# MCAN register map
Vendor: Texas Instruments
Peripheral module from a debugger description file (folder UCD3138R064RSM).
Registers are 32-bit, access per field, no defined reset value unless marked. A register's access mark holds for its fields unless they carry their own. Offsets are as the file gives them; lines under a group give offsets from that group; [hi:lo] are bit positions; {n}, {i} and the like mark numbered series; 'fields as' and 'values as' point back to an identical list; <NAME> marks a mode.

## MCAN (part 1 of 2)
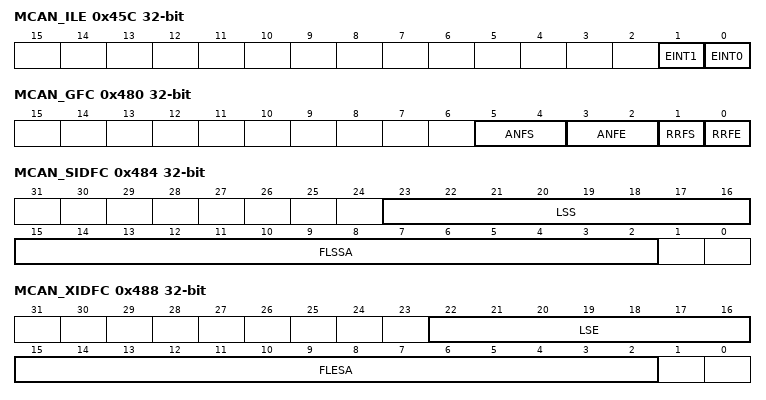
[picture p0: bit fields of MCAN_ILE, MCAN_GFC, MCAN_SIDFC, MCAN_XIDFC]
0x45C MCAN_ILE — MCAN Interrupt Line Enable
  [1] EINT1 rw — Enable Interrupt Line 1 #br# 0 Interrupt Line 1 is disabled #br# 1 Interrupt Line 1 is enabled
  [0] EINT0 rw — Enable Interrupt Line 0 #br# 0 Interrupt Line 0 is disabled #br# 1 Interrupt Line 0 is enabled
0x480 MCAN_GFC — MCAN Global Filter Configuration
  [5:4] ANFS rw — Accept Non-matching Frames Standard. Defines how received messages with 11-bit IDs that do not match any element of the filter list are treated. #br# 00 Accept in Rx FIFO 0 #br# 01 Accept in Rx FIFO 1 #br# 10 Reject #br# 11 Reject #br# #br#Qualified Write is possible only with CCCR.CCE='1' and CCCR.INIT='1'.
  [3:2] ANFE rw — Accept Non-matching Frames Extended. Defines how received messages with 29-bit IDs that do not match any element of the filter list are treated. #br# 00 Accept in Rx FIFO 0 #br# 01 Accept in Rx FIFO 1 #br# 10 Reject #br# 11 Reject #br# #br#Qualified Write is possible only with CCCR.CCE='1' and CCCR.INIT='1'.
  [1] RRFS rw — Reject Remote Frames Standard #br# 0 Filter remote frames with 11-bit standard IDs #br# 1 Reject all remote frames with 11-bit standard IDs #br# #br#Qualified Write is possible only with CCCR.CCE='1' and CCCR.INIT='1'.
  [0] RRFE rw — Reject Remote Frames Extended #br# 0 Filter remote frames with 29-bit extended IDs #br# 1 Reject all remote frames with 29-bit extended IDs #br# #br#Qualified Write is possible only with CCCR.CCE='1' and CCCR.INIT='1'.
0x484 MCAN_SIDFC — MCAN Standard ID Filter Configuration
  [23:16] LSS rw — List Size Standard #br# 0 No standard Message ID filter #br# 1-128 Number of standard Message ID filter elements #br# >128 Values greater than 128 are interpreted as 128
  [15:2] FLSSA rw — Filter List Standard Start Address. Start address of standard Message ID filter list (32-bit word address).
0x488 MCAN_XIDFC — MCAN Extended ID Filter Configuration
  [22:16] LSE rw — List Size Extended #br# 0 No extended Message ID filter #br# 1-64 Number of extended Message ID filter elements #br# >64 Values greater than 64 are interpreted as 64 #br# #br#Qualified Write is possible only with CCCR.CCE='1' and CCCR.INIT='1'.
  [15:2] FLESA rw — Filter List Extended Start Address. Start address of extended Message ID filter list (32-bit word address). #br# #br#Qualified Write is possible only with CCCR.CCE='1' and CCCR.INIT='1'.
0x490 MCAN_XIDAM — MCAN Extended ID and Mask
  [28:0] EIDM rw — Extended ID Mask. For acceptance filtering of extended frames the Extended ID AND Mask is ANDed with the Message ID of a received frame. Intended for masking of 29-bit IDs in SAE J1939. With the reset value of all bits set to one the mask is not active. #br# #br#Qualified Write is possible only with CCCR.CCE='1' and CCCR.INIT='1'.
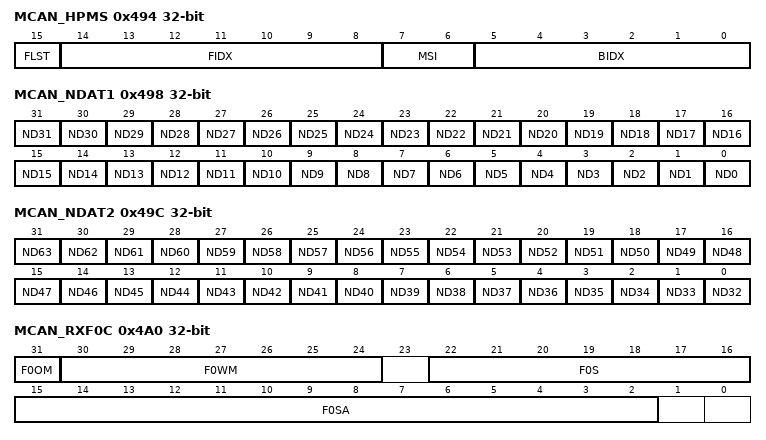
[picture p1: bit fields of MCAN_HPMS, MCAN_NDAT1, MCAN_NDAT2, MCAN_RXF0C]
0x494 MCAN_HPMS ro — This register is updated every time a Message ID filter element configured to generate a priority event matches. This can be used to monitor the status of incoming high priority messages and to enable fast access to these messages.
  [15] FLST — Filter List. Indicates the filter list of the matching filter element. #br# 0 Standard Filter List #br# 1 Extended Filter List
  [14:8] FIDX — Filter Index. Index of matching filter element. Range is 0 to SIDFC.LSS - 1 resp. XIDFC.LSE - 1.
  [7:6] MSI — Message Storage Indicator #br# 00 No FIFO selected #br# 01 FIFO message lost #br# 10 Message stored in FIFO 0 #br# 11 Message stored in FIFO 1
  [5:0] BIDX — Buffer Index. Index of Rx FIFO element to which the message was stored. Only valid when MSI[1] = '1'.
0x498 MCAN_NDAT1 rw — MCAN New Data 1
  [n] ND{n} (n=0..31) — New Data RX Buffer {n} #br# 0 Rx Buffer not updated #br# 1 Rx Buffer updated from new message
0x49C MCAN_NDAT2 rw — MCAN New Data 2
  [n-32] ND{n} (n=32..63) — New Data RX Buffer {n} #br# 0 Rx Buffer not updated #br# 1 Rx Buffer updated from new message
0x4A0 MCAN_RXF0C — MCAN Rx FIFO 0 Configuration
  [31] F0OM rw — FIFO 0 Operation Mode. FIFO 0 can be operated in blocking or in overwrite mode. #br# 0 FIFO 0 blocking mode #br# 1 FIFO 0 overwrite mode #br# #br#Qualified Write is possible only with CCCR.CCE='1' and CCCR.INIT='1'.
  [30:24] F0WM rw — Rx FIFO 0 Watermark #br# 0 Watermark interrupt disabled #br# 1-64 Level for Rx FIFO 0 watermark interrupt (IR.RF0W) #br# >64 Watermark interrupt disabled #br# #br#Qualified Write is possible only with CCCR.CCE='1' and CCCR.INIT='1'.
  [22:16] F0S rw — Rx FIFO 0 Size. The Rx FIFO 0 elements are indexed from 0 to F0S-1. #br# 0 No Rx FIFO 0 #br# 1-64 Number of Rx FIFO 0 elements #br# >64 Values greater than 64 are interpreted as 64 #br# #br#Qualified Write is possible only with CCCR.CCE='1' and CCCR.INIT='1'.
  [15:2] F0SA rw — Rx FIFO 0 Start Address. Start address of Rx FIFO 0 in Message RAM (32-bit word address). #br# #br#Qualified Write is possible only with CCCR.CCE='1' and CCCR.INIT='1'.
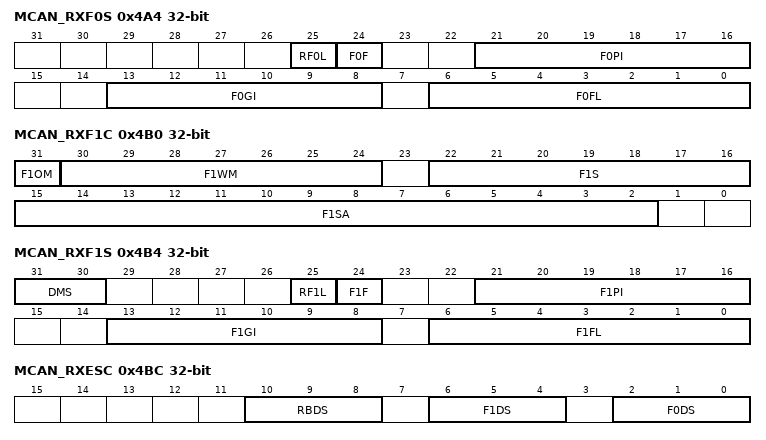
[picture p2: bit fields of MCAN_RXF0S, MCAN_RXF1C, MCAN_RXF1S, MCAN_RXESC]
0x4A4 MCAN_RXF0S ro — MCAN Rx FIFO 0 Status
  [25] RF0L — Rx FIFO 0 Message Lost. This bit is a copy of interrupt flag IR.RF0L. When IR.RF0L is reset, this bit is also reset. #br# 0 No Rx FIFO 0 message lost #br# 1 Rx FIFO 0 message lost, also set after write attempt to Rx FIFO 0 of size zero #br# #br#Note: Overwriting the oldest message when RXF0C.F0OM = '1' will not set this flag.
  [24] F0F — Rx FIFO 0 Full #br# 0 Rx FIFO 0 not full #br# 1 Rx FIFO 0 full
  [21:16] F0PI — Rx FIFO 0 Put Index. Rx FIFO 0 write index pointer, range 0 to 63.
  [13:8] F0GI — Rx FIFO 0 Get Index. Rx FIFO 0 read index pointer, range 0 to 63.
  [6:0] F0FL — Rx FIFO 0 Fill Level. Number of elements stored in Rx FIFO 0, range 0 to 64.
0x4A8 MCAN_RXF0A — MCAN Rx FIFO 0 Acknowledge
  [5:0] F0AI rw — Rx FIFO 0 Acknowledge Index. After the Host has read a message or a sequence of messages from Rx FIFO 0 it has to write the buffer index of the last element read from Rx FIFO 0 to F0AI. This will set the Rx FIFO 0 Get Index RXF0S.F0GI to F0AI + 1 and update the FIFO 0 Fill Level RXF0S.F0FL.
0x4AC MCAN_RXBC — MCAN Rx Buffer Configuration
  [15:2] RBSA rw — Rx Buffer Start Address. Configures the start address of the Rx Buffers section in the Message RAM (32-bit word address). #br# #br#+I466
0x4B0 MCAN_RXF1C — MCAN Rx FIFO 1 Configuration
  [31] F1OM rw — FIFO 1 Operation Mode. FIFO 1 can be operated in blocking or in overwrite mode. #br# 0 FIFO 1 blocking mode #br# 1 FIFO 1 overwrite mode #br# #br#Qualified Write is possible only with CCCR.CCE='1' and CCCR.INIT='1'.
  [30:24] F1WM rw — Rx FIFO 1 Watermark #br# 0 Watermark interrupt disabled #br# 1-64 Level for Rx FIFO 1 watermark interrupt (IR.RF1W) #br# >64 Watermark interrupt disabled #br# #br#Qualified Write is possible only with CCCR.CCE='1' and CCCR.INIT='1'.
  [22:16] F1S rw — Rx FIFO 1 Size. The Rx FIFO 1 elements are indexed from 0 to F1S - 1. #br# 0 No Rx FIFO 1 #br# 1-64 Number of Rx FIFO 1 elements #br# >64 Values greater than 64 are interpreted as 64 #br# #br#Qualified Write is possible only with CCCR.CCE='1' and CCCR.INIT='1'.
  [15:2] F1SA rw — Rx FIFO 1 Start Address Start address of Rx FIFO 1 in Message RAM (32-bit word address).
0x4B4 MCAN_RXF1S ro — MCAN Rx FIFO 1 Status
  [31:30] DMS — Debug Message Status #br# 00 Idle state, wait for reception of debug messages, DMA request is cleared #br# 01 Debug message A received #br# 10 Debug messages A, B received #br# 11 Debug messages A, B, C received, DMA request is set
  [25] RF1L — Rx FIFO 1 Message Lost. This bit is a copy of interrupt flag IR.RF1L. When IR.RF1L is reset, this bit is also reset. #br# 0 No Rx FIFO 1 message lost #br# 1 Rx FIFO 1 message lost, also set after write attempt to Rx FIFO 1 of size zero #br# #br#Note: Overwriting the oldest message when RXF1C.F1OM = '1' will not set this flag.
  [24] F1F — Rx FIFO 1 Full #br# 0 Rx FIFO 1 not full #br# 1 Rx FIFO 1 full
  [21:16] F1PI — Rx FIFO 1 Put Index. Rx FIFO 1 write index pointer, range 0 to 63.
  [13:8] F1GI — Rx FIFO 1 Get Index. Rx FIFO 1 read index pointer, range 0 to 63.
  [6:0] F1FL — Rx FIFO 1 Fill Level. Number of elements stored in Rx FIFO 1, range 0 to 64.
0x4B8 MCAN_RXF1A — MCAN Rx FIFO 1 Acknowledge
  [5:0] F1AI rw — Rx FIFO 1 Acknowledge Index. After the Host has read a message or a sequence of messages from Rx FIFO 1 it has to write the buffer index of the last element read from Rx FIFO 1 to F1AI. This will set the Rx FIFO 1 Get Index RXF1S.F1GI to F1AI + 1 and update the FIFO 1 Fill Level RXF1S.F1FL.
0x4BC MCAN_RXESC — Configures the number of data bytes belonging to an Rx Buffer / Rx FIFO element. Data field sizes >8 bytes are intended for CAN FD operation only.
  [10:8] RBDS rw — Rx Buffer Data Field Size #br# 000 8 byte data field #br# 001 12 byte data field #br# 010 16 byte data field #br# 011 20 byte data field #br# 100 24 byte data field #br# 101 32 byte data field #br# 110 48 byte data field #br# 111 64 byte data field #br# #br#Note: In case the data field size of an accepted CAN frame exceeds the data field size configured for the matching Rx Buffer or Rx FIFO, only the number of bytes as configured by RXESC are stored to the Rx Buffer resp. Rx FIFO element. The rest of the frame's data field is ignored. #br# #br#Qualified Write is possible only with CCCR.CCE='1' and CCCR.INIT='1'.
  [6:4] F1DS rw — Rx FIFO 1 Data Field Size #br# 000 8 byte data field #br# 001 12 byte data field #br# 010 16 byte data field #br# 011 20 byte data field #br# 100 24 byte data field #br# 101 32 byte data field #br# 110 48 byte data field #br# 111 64 byte data field #br# #br#Note: In case the data field size of an accepted CAN frame exceeds the data field size configured for the matching Rx Buffer or Rx FIFO, only the number of bytes as configured by RXESC are stored to the Rx Buffer resp. Rx FIFO element. The rest of the frame's data field is ignored. #br# #br#Qualified Write is possible only with CCCR.CCE='1' and CCCR.INIT='1'.
  [2:0] F0DS rw — Rx FIFO 0 Data Field Size #br# 000 8 byte data field #br# 001 12 byte data field #br# 010 16 byte data field #br# 011 20 byte data field #br# 100 24 byte data field #br# 101 32 byte data field #br# 110 48 byte data field #br# 111 64 byte data field #br# #br#Note: In case the data field size of an accepted CAN frame exceeds the data field size configured for the matching Rx Buffer or Rx FIFO, only the number of bytes as configured by RXESC are stored to the Rx Buffer resp. Rx FIFO element. The rest of the frame's data field is ignored. #br# #br#Qualified Write is possible only with CCCR.CCE='1' and CCCR.INIT='1'.
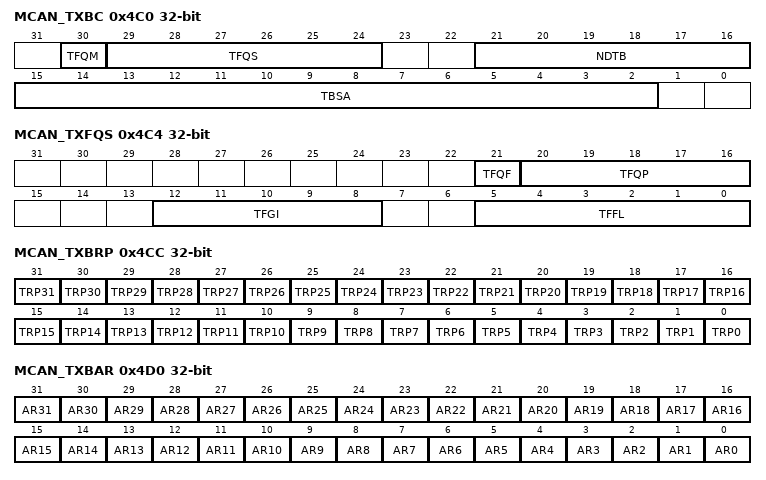
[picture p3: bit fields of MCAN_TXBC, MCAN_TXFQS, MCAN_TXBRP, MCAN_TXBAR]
0x4C0 MCAN_TXBC — MCAN Tx Buffer Configuration
  [30] TFQM rw — Tx FIFO/Queue Mode #br# 0 Tx FIFO operation #br# 1 Tx Queue operation #br# #br#Qualified Write is possible only with CCCR.CCE='1' and CCCR.INIT='1'.
  [29:24] TFQS rw — Transmit FIFO/Queue Size #br# 0 No Tx FIFO/Queue #br# 1-32 Number of Tx Buffers used for Tx FIFO/Queue #br# >32 Values greater than 32 are interpreted as 32 #br# #br#Note: Be aware that the sum of TFQS and NDTB may be not greater than 32. There is no check #br#for erroneous configurations. The Tx Buffers section in the Message RAM starts with the #br#dedicated Tx Buffers. #br# #br#Qualified Write is possible only with CCCR.CCE='1' and CCCR.INIT='1'.
  [21:16] NDTB rw — Number of Dedicated Transmit Buffers #br# 0 No Dedicated Tx Buffers #br# 1-32 Number of Dedicated Tx Buffers #br# >32 Values greater than 32 are interpreted as 32 #br# #br#Note: Be aware that the sum of TFQS and NDTB may be not greater than 32. There is no check #br#for erroneous configurations. The Tx Buffers section in the Message RAM starts with the #br#dedicated Tx Buffers. #br# #br#Qualified Write is possible only with CCCR.CCE='1' and CCCR.INIT='1'.
  [15:2] TBSA rw — Tx Buffers Start Address. Start address of Tx Buffers section in Message RAM (32-bit word address). #br# #br#Qualified Write is possible only with CCCR.CCE='1' and CCCR.INIT='1'.
0x4C4 MCAN_TXFQS ro — The Tx FIFO/Queue status is related to the pending Tx requests listed in register TXBRP. Therefore the effect of Add/Cancellation requests may be delayed due to a running Tx scan (TXBRP not yet updated).
  [21] TFQF — Tx FIFO/Queue Full #br# 0 Tx FIFO/Queue not full #br# 1 Tx FIFO/Queue full
  [20:16] TFQP — Tx FIFO/Queue Put Index. Tx FIFO/Queue write index pointer, range 0 to 31. #br# #br#Note: In case of mixed configurations where dedicated Tx Buffers are combined with a Tx FIFO or a Tx Queue, the Put and Get Indices indicate the number of the Tx Buffer starting with the first dedicated Tx Buffers. Example: For a configuration of 12 dedicated Tx Buffers and a Tx FIFO of 20 Buffers a Put Index of 15 points to the fourth buffer of the Tx FIFO.
  [12:8] TFGI — Tx FIFO Get Index. Tx FIFO read index pointer, range 0 to 31. Read as zero when Tx Queue operation is configured (TXBC.TFQM = '1'). #br# #br#Note: In case of mixed configurations where dedicated Tx Buffers are combined with a Tx FIFO or a Tx Queue, the Put and Get Indices indicate the number of the Tx Buffer starting with the first dedicated Tx Buffers. Example: For a configuration of 12 dedicated Tx Buffers and a Tx FIFO of 20 Buffers a Put Index of 15 points to the fourth buffer of the Tx FIFO.
  [5:0] TFFL — Tx FIFO Free Level. Number of consecutive free Tx FIFO elements starting from TFGI, range 0 to 32. Read as zero when Tx Queue operation is configured (TXBC.TFQM = '1').
0x4C8 MCAN_TXESC — Configures the number of data bytes belonging to a Tx Buffer element. Data field sizes > 8 bytes are intended for CAN FD operation only.
  [2:0] TBDS rw — Tx Buffer Data Field Size #br# 000 8 byte data field #br# 001 12 byte data field #br# 010 16 byte data field #br# 011 20 byte data field #br# 100 24 byte data field #br# 101 32 byte data field #br# 110 48 byte data field #br# 111 64 byte data field #br# #br#Note: In case the data length code DLC of a Tx Buffer element is configured to a value higher than the Tx Buffer data field size TXESC.TBDS, the bytes not defined by the Tx Buffer are transmitted as "0xCC" (padding bytes). #br# #br#Qualified Write is possible only with CCCR.CCE='1' and CCCR.INIT='1'.
0x4CC MCAN_TXBRP ro — MCAN Tx Buffer Request Pending
  [n] TRP{n} (n=1..31) — Transmission Request Pending {n}. See description for bit 0.
  [0] TRP0 — Transmission Request Pending 0. #br# #br#Each Tx Buffer has its own Transmission Request Pending bit. The bits are set via register TXBAR. The bits are reset after a requested transmission has completed or has been cancelled via register TXBCR. #br# #br#TXBRP bits are set only for those Tx Buffers configured via TXBC. After a TXBRP bit has been set, a Tx scan is started to check for the pending Tx request with the highest priority (Tx Buffer with lowest Message ID). #br# #br#A cancellation request resets the corresponding transmission request pending bit of register TXBRP. In case a transmission has already been started when a cancellation is requested, this is done at the end of the transmission, regardless whether the transmission was successful or not. The cancellation request bits are reset directly after the corresponding TXBRP bit has been reset. #br# #br#After a cancellation has been requested, a finished cancellation is signalled via TXBCF #br#- after successful transmission together with the corresponding TXBTO bit #br#- when the transmission has not yet been started at the point of cancellation #br#- when the transmission has been aborted due to lost arbitration #br#- when an error occurred during frame transmission #br# #br#In DAR mode all transmissions are automatically cancelled if they are not successful. The corresponding TXBCF bit is set for all unsuccessful transmissions. #br# 0 No transmission request pending #br# 1 Transmission request pending #br# #br#Note: TXBRP bits which are set while a Tx scan is in progress are not considered during this particular Tx scan. In case a cancellation is requested for such a Tx Buffer, this Add Request is cancelled immediately, the corresponding TXBRP bit is reset.
0x4D0 MCAN_TXBAR rw — MCAN Tx Buffer Add Request
  [n] AR{n} (n=1..31) — Add Request {n}. See description for bit 0.
  [0] AR0 — Add Request 0. #br# #br#Each Tx Buffer has its own Add Request bit. Writing a '1' will set the corresponding Add Request bit; writing a '0' has no impact. This enables the Host to set transmission requests for multiple Tx Buffers with one write to TXBAR. TXBAR bits are set only for those Tx Buffers configured via TXBC. When no Tx scan is running, the bits are reset immediately, else the bits remain set until the Tx scan process has completed. #br# 0 No transmission request added #br# 1 Transmission requested added #br# #br#Note: If an add request is applied for a Tx Buffer with pending transmission request (corresponding TXBRP bit already set), this add request is ignored. #br# #br#Qualified Write is possible only with CCCR.CCE='0'
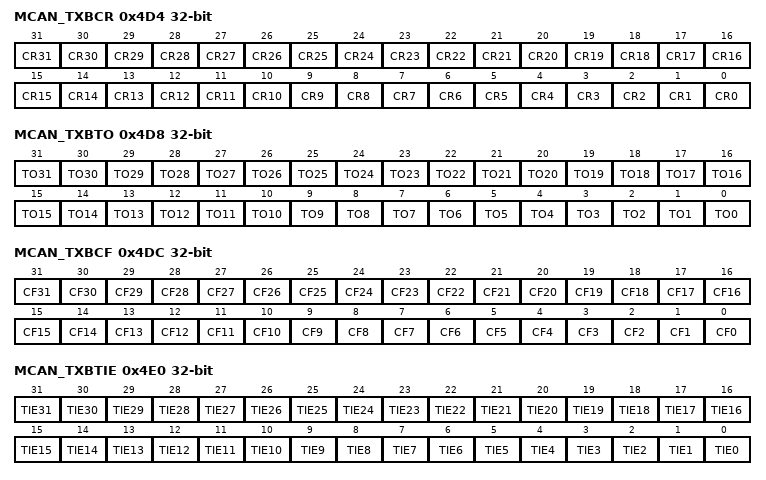
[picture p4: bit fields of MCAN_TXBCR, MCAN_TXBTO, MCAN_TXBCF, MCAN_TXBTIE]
0x4D4 MCAN_TXBCR rw — MCAN Tx Buffer Cancellation Request
  [n] CR{n} (n=1..31) — Cancellation Request {n}. See description for bit 0.
  [0] CR0 — Cancellation Request 0. #br# #br#Each Tx Buffer has its own Cancellation Request bit. Writing a '1' will set the corresponding Cancellation Request bit; writing a '0' has no impact. This enables the Host to set cancellation requests for multiple Tx Buffers with one write to TXBCR. TXBCR bits are set only for those Tx Buffers configured via TXBC. The bits remain set until the corresponding bit of TXBRP is reset. #br# 0 No cancellation pending #br# 1 Cancellation pending #br# #br#Qualified Write is possible only with CCCR.CCE='0'
0x4D8 MCAN_TXBTO ro — MCAN Tx Buffer Transmission Occurred
  [n] TO{n} (n=1..31) — Transmission Occurred {n}. See description for bit 0.
  [0] TO0 — Transmission Occurred 0. #br# #br#Each Tx Buffer has its own Transmission Occurred bit. The bits are set when the corresponding TXBRP bit is cleared after a successful transmission. The bits are reset when a new transmission is requested by writing a '1' to the corresponding bit of register TXBAR. #br# 0 No transmission occurred #br# 1 Transmission occurred
0x4DC MCAN_TXBCF ro — MCAN Tx Buffer Cancellation Finished
  [n] CF{n} (n=1..31) — Cancellation Finished {n}. See description for bit 0.
  [0] CF0 — Cancellation Finished 0. #br# #br#Each Tx Buffer has its own Cancellation Finished bit. The bits are set when the corresponding TXBRP bit is cleared after a cancellation was requested via TXBCR. In case the corresponding TXBRP bit was not set at the point of cancellation, CF is set immediately. The bits are reset when a new transmission is requested by writing a '1' to the corresponding bit of register TXBAR. #br# 0 No transmit buffer cancellation #br# 1 Transmit buffer cancellation finished
0x4E0 MCAN_TXBTIE rw — Each Tx Buffer has its own Transmission Interrupt Enable bit.
  [n] TIE{n} (n=1..31) — Transmission Interrupt Enable {n}. Each Tx Buffer has its own Transmission Interrupt Enable bit. #br# 0 Transmission interrupt disabled #br# 1 Transmission interrupt enable
  [0] TIE0 — Transmission Interrupt Enable 0. #br# 0 Transmission interrupt disabled #br# 1 Transmission interrupt enable
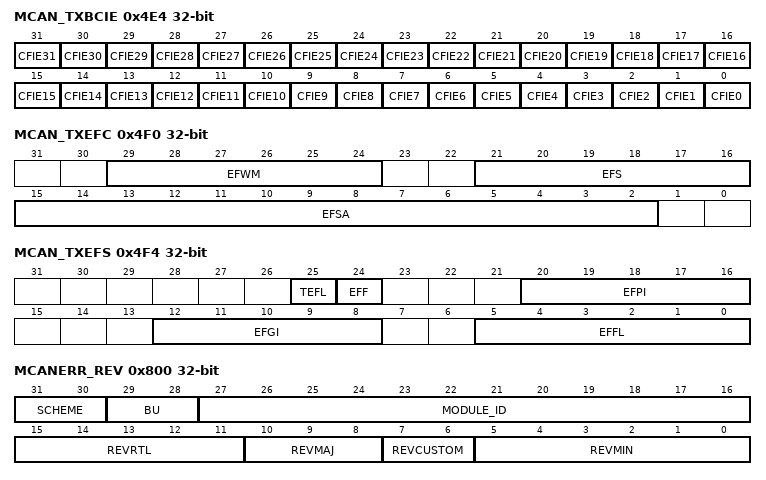
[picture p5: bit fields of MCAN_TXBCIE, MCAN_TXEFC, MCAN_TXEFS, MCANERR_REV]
0x4E4 MCAN_TXBCIE rw — MCAN Tx Buffer Cancellation Finished Interrupt Enable
  [n] CFIE{n} (n=0..31) — Cancellation Finished Interrupt Enable {n}. Each Tx Buffer has its own Cancellation Finished Interrupt Enable bit. #br# 0 Cancellation finished interrupt disabled #br# 1 Cancellation finished interrupt enabled
0x4F0 MCAN_TXEFC — MCAN Tx Event FIFO Configuration
  [29:24] EFWM rw — Event FIFO Watermark #br# 0 Watermark interrupt disabled #br# 1-32 Level for Tx Event FIFO watermark interrupt (IR.TEFW) #br# >32 Watermark interrupt disabled
  [21:16] EFS rw — Event FIFO Size. The Tx Event FIFO elements are indexed from 0 to EFS - 1. #br# 0 Tx Event FIFO disabled #br# 1-32 Number of Tx Event FIFO elements #br# >32 Values greater than 32 are interpreted as 32
  [15:2] EFSA rw — Event FIFO Start Address. Start address of Tx Event FIFO in Message RAM (32-bit word address).
0x4F4 MCAN_TXEFS ro — MCAN Tx Event FIFO Status
  [25] TEFL — Tx Event FIFO Element Lost. This bit is a copy of interrupt flag IR.TEFL. When IR.TEFL is reset, this bit is also reset. #br# 0 No Tx Event FIFO element lost #br# 1 Tx Event FIFO element lost, also set after write attempt to Tx Event FIFO of size zero.
  [24] EFF — Event FIFO Full #br# 0 Tx Event FIFO not full #br# 1 Tx Event FIFO full
  [20:16] EFPI — Event FIFO Put Index.Tx Event FIFO write index pointer, range 0 to 31.
  [12:8] EFGI — Event FIFO Get Index. Tx Event FIFO read index pointer, range 0 to 31.
  [5:0] EFFL — Event FIFO Fill Level. Number of elements stored in Tx Event FIFO, range 0 to 32.
0x4F8 MCAN_TXEFA — MCAN Tx Event FIFO Acknowledge
  [4:0] EFAI rw — Event FIFO Acknowledge Index. After the Host has read an element or a sequence of elements from the Tx Event FIFO it has to write the index of the last element read from Tx Event FIFO to EFAI. This will set the Tx Event FIFO Get Index TXEFS.EFGI to EFAI + 1 and update the Event FIFO Fill Level TXEFS.EFFL.
0x800 MCANERR_REV ro — MCAN Error Aggregator Revision Register
  [31:30] SCHEME — PID Register Scheme
  [29:28] BU — Business Unit: 0x2 = Processors
  [27:16] MODULE_ID — Module Identification Number
  [15:11] REVRTL — RTL revision. Will vary depending on release
  [10:8] REVMAJ — Major Revision of the Error Aggregator
  [7:6] REVCUSTOM — Custom Revision of the Error Aggregator
  [5:0] REVMIN — Minor Revision of the Error Aggregator
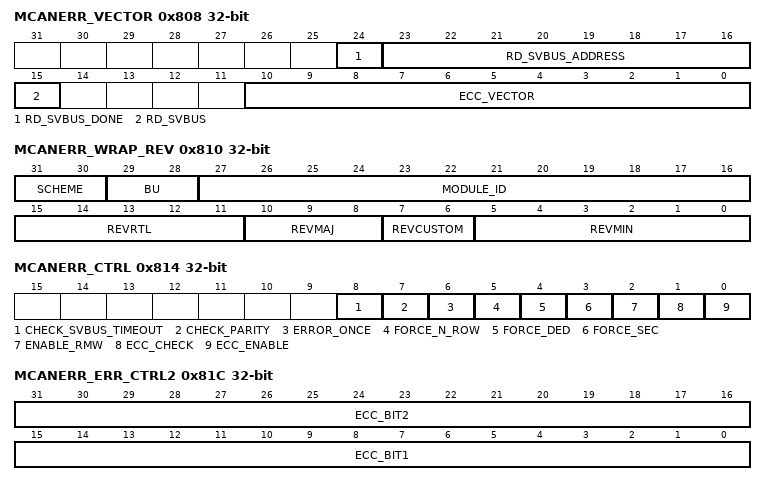
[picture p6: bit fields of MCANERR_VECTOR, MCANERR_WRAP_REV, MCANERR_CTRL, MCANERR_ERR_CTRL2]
0x808 MCANERR_VECTOR — Each error detection and correction (EDC) controller has a bank of error registers (offsets 0x10 - 0x3B) associated with it. These registers are accessed via an internal serial bus (SVBUS). To access them through the ECC aggregator the controller ID desired must be written to the ECC_VECTOR field, together with the RD_SVBUS trigger and RD_SVBUS_ADDRESS bit field. This initiates the serial read which consummates by setting the RD_SVBUS_DONE bit. At this point the addressed register may be read by a normal CPU read of the appropriate offset address.
  [24] RD_SVBUS_DONE ro — Read Completion Flag
  [23:16] RD_SVBUS_ADDRESS rw — Read Address Offset
  [15] RD_SVBUS rw — Read Trigger
  [10:0] ECC_VECTOR rw — ECC RAM ID. Each error detection and correction (EDC) controller has a bank of error registers (offsets 0x10 - 0x3B) associated with it. These registers are accessed via an internal serial bus (SVBUS). To access them through the ECC aggregator the controller ID desired must be written to the ECC_VECTOR field, together with the RD_SVBUS trigger and RD_SVBUS_ADDRESS bit field. This initiates the serial read which consummates by setting the RD_SVBUS_DONE bit. At this point the addressed register may be read by a normal CPU read of the appropriate offset address. #br# 0x000 Message RAM ECC controller is selected #br# Others Reserved (do not use) #br# #br#Subsequent writes through the SVBUS (offsets 0x10 - 0x3B) have a delayed completion. To avoid conflicts, perform a read back of a register within this range after writing.
0x80C MCANERR_STAT ro — MCAN Error Misc Status
  [10:0] NUM_RAMS — Number of RAMs. Number of ECC RAMs serviced by the aggregator.
0x810 MCANERR_WRAP_REV ro — This register is accessed through the ECC aggregator via an internal serial bus. To access, the appropriate procedure must be first followed in the MCAN ECC Vector Register.
  fields as MCANERR_REV
0x814 MCANERR_CTRL — This register is accessed through the ECC aggregator via an internal serial bus. To access, the appropriate procedure must be first followed in the MCAN ECC Vector Register.
  [8] CHECK_SVBUS_TIMEOUT rw — Enables Serial VBUS timeout mechanism
  [7] CHECK_PARITY rw — Enables parity checking on internal data
  [6] ERROR_ONCE rw — If this bit is set, the FORCE_SEC/FORCE_DED will inject an error to the specified row only once. The FORCE_SEC bit will be cleared once a writeback happens. If writeback is not enabled, this error will be cleared the cycle following the read when the data is corrected. For double-bit errors, the FORCE_DED bit will be cleared the cycle following the double-bit error. Any subsequent reads will not force an error.
  [5] FORCE_N_ROW rw — Enable single/double-bit error on the next RAM read, regardless of the MCANERR_ERR_CTRL1.ECC_ROW setting. For write through mode, this applies to writes as well as reads.
  [4] FORCE_DED rw — Force double-bit error. Cleared the cycle following the error if ERROR_ONCE is asserted. For write through mode, this applies to writes as well as reads. MCANERR_ERR_CTRL1 and MCANERR_ERR_CTRL2 should be configured prior to setting this bit.
  [3] FORCE_SEC rw — Force single-bit error. Cleared on a writeback or the cycle following the error if ERROR_ONCE is asserted. For write through mode, this applies to writes as well as reads. MCANERR_ERR_CTRL1 and MCANERR_ERR_CTRL2 should be configured prior to setting this bit.
  [2] ENABLE_RMW rw — Enable read-modify-write on partial word writes
  [1] ECC_CHECK rw — Enable ECC Check. ECC is completely bypassed if both ECC_ENABLE and ECC_CHECK are '0'.
  [0] ECC_ENABLE rw — Enable ECC Generation
0x818 MCANERR_ERR_CTRL1 rw — This register is accessed through the ECC aggregator via an internal serial bus. To access, the appropriate procedure must be first followed in the MCAN ECC Vector Register.
  [31:0] ECC_ROW — Row address where FORCE_SEC or FORCE_DED needs to be applied. This is ignored if FORCE_N_ROW is set.
0x81C MCANERR_ERR_CTRL2 rw — This register is accessed through the ECC aggregator via an internal serial bus. To access, the appropriate procedure must be first followed in the MCAN ECC Vector Register.
  [31:16] ECC_BIT2 — Second column/data bit that needs to be flipped when FORCE_DED is set
  [15:0] ECC_BIT1 — Column/Data bit that needs to be flipped when FORCE_SEC or FORCE_DED is set
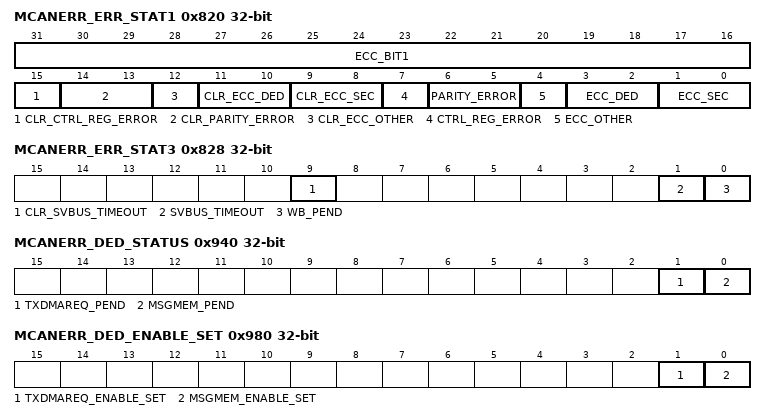
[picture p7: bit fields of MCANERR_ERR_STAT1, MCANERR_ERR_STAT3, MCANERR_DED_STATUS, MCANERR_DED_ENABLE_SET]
0x820 MCANERR_ERR_STAT1 — This register is accessed through the ECC aggregator via an internal serial bus. To access, the appropriate procedure must be first followed in the MCAN ECC Vector Register.
  [31:16] ECC_BIT1 ro — ECC Error Bit Position. Indicates the bit position in the RAM data that is in error on an SEC error. Only valid on an SEC error. #br# 0 Bit 0 is in error #br# 1 Bit 1 is in error #br# 2 Bit 2 is in error #br# 3 Bit 3 is in error #br# ... #br# 31 Bit 31 is in error #br# >32 Invalid
  [15] CLR_CTRL_REG_ERROR rw — Writing a '1' clears the CTRL_REG_ERROR bit
  [14:13] CLR_PARITY_ERROR rw — Clear Parity Error. A write of a non-zero value to this bit field decrements the PARITY_ERROR bit field by the value provided.
  [12] CLR_ECC_OTHER rw — Writing a '1' clears the ECC_OTHER bit.
  [11:10] CLR_ECC_DED rw — Clear ECC_DED. A write of a non-zero value to this bit field decrements the ECC_DED bit field by the value provided.
  [9:8] CLR_ECC_SEC rw — Clear ECC_SEC. A write of a non-zero value to this bit field decrements the ECC_SEC bit field by the value provided.
  [7] CTRL_REG_ERROR rw — Control Register Error. A bit field in the control register is in an ambiguous state. This means that the redundancy registers have detected a state where not all values are the same and has defaulted to the reset state. S/W needs to re-write these registers to a known state. A write of 1 will set this interrupt flag.
  [6:5] PARITY_ERROR rw — Parity Error Status. A 2-bit saturating counter of the number of parity errors that have occurred since last cleared. #br# #br# 0 No parity error detected #br# 1 One parity error was detected #br# 2 Two parity errors were detected #br# 3 Three parity errors were detected #br# #br#A write of a non-zero value to this bit field increments it by the value provided.
  [4] ECC_OTHER rw — SEC While Writeback Error Status #br# 0 No SEC error while writeback pending #br# 1 Indicates that successive single-bit errors have occurred while a writeback is still pending
  [3:2] ECC_DED rw — Double Bit Error Detected Status. A 2-bit saturating counter of the number of DED errors that have occurred since last cleared. #br# #br# 0 No double-bit error detected #br# 1 One double-bit error was detected #br# 2 Two double-bit errors were detected #br# 3 Three double-bit errors were detected #br# #br#A write of a non-zero value to this bit field increments it by the value provided.
  [1:0] ECC_SEC rw — Single Bit Error Corrected Status. A 2-bit saturating counter of the number of SEC errors that have occurred since last cleared. #br# #br# 0 No single-bit error detected #br# 1 One single-bit error was detected and corrected #br# 2 Two single-bit errors were detected and corrected #br# 3 Three single-bit errors were detected and corrected #br# #br#A write of a non-zero value to this bit field increments it by the value provided.
0x824 MCANERR_ERR_STAT2 ro — This register is accessed through the ECC aggregator via an internal serial bus. To access, the appropriate procedure must be first followed in the MCAN ECC Vector Register.
  [31:0] ECC_ROW — Indicates the row address where the single or double-bit error occurred. This value is address offset/4.
0x828 MCANERR_ERR_STAT3 — This register is accessed through the ECC aggregator via an internal serial bus. To access, the appropriate procedure must be first followed in the MCAN ECC Vector Register.
  [9] CLR_SVBUS_TIMEOUT rw — Write 1 to clear the Serial VBUS Timeout Flag
  [1] SVBUS_TIMEOUT rw — Serial VBUS Timeout Flag. Write 1 to set.
  [0] WB_PEND ro — Delayed Write Back Pending Status #br# 0 No write back pending #br# 1 An ECC data correction write back is pending
0x83C MCANERR_SEC_EOI — MCAN Single Error Corrected End of Interrupt Register
  [0] EOI_WR rw — Write to this register indicates that software has acknowledged the pending interrupt and the next interrupt can be sent to the host. #br# #br#Note that a write to the MCANERR_ERR_STAT1.CLR_ECC_SEC goes through the SVBUS and has a delayed completion. To avoid an additional interrupt, read the MCANERR_ERR_STAT1 register back prior to writing to this bit field.
0x840 MCANERR_SEC_STATUS — MCAN Single Error Corrected Interrupt Status Register
  [0] MSGMEM_PEND rw — Message RAM SEC Interrupt Pending #br# 0 No SEC interrupt is pending #br# 1 SEC interrupt is pending
0x880 MCANERR_SEC_ENABLE_SET — MCAN Single Error Corrected Interrupt Enable Set Register
  [0] MSGMEM_ENABLE_SET rw — Message RAM SEC Interrupt Pending Enable Set. Writing a 1 to this bit enables the Message RAM SEC error interrupts. Writing a 0 has no effect. Reads return the corresponding enable bit's current value.
0x8C0 MCANERR_SEC_ENABLE_CLR — MCAN Single Error Corrected Interrupt Enable Clear Register
  [0] MSGMEM_ENABLE_CLR rw — Message RAM SEC Interrupt Pending Enable Clear. Writing a 1 to this bit disables the Message RAM SEC error interrupts. Writing a 0 has no effect. Reads return the corresponding enable bit's current value.
0x93C MCANERR_DED_EOI — MCAN Double Error Detected End of Interrupt Register
  [0] EOI_WR rw — Write to this register indicates that software has acknowledged the pending interrupt and the next interrupt can be sent to the host. #br# #br#Note that a write to the MCANERR_ERR_STAT1.CLR_ECC_DED goes through the SVBUS and has a delayed completion. To avoid an additional interrupt, read the MCANERR_ERR_STAT1 register back prior to writing to this bit field.
0x940 MCANERR_DED_STATUS — MCAN Double Error Detected Interrupt Status Register
  [1] TXDMAREQ_PEND rw — TX Empty DMA Request Parity Interrupt Pending #br# 0 No parity error interrupt is pending #br# 1 A parity error interrupt is pending
  [0] MSGMEM_PEND rw — Message RAM DED Interrupt Pending #br# 0 No DED interrupt is pending #br# 1 DED interrupt is pending
0x980 MCANERR_DED_ENABLE_SET — MCAN Double Error Detected Interrupt Enable Set Register
  [1] TXDMAREQ_ENABLE_SET rw — TX Empty DMA Request Parity Interrupt Pending Enable Set. Writing a 1 to this bit enables the TX empty DMA request parity error interrupts. Writing a 0 has no effect. Reads return the corresponding enable bit's current value.
  [0] MSGMEM_ENABLE_SET rw — Message RAM DED Interrupt Pending Enable Set. Writing a 1 to this bit enables the Message RAM DED error interrupts. Writing a 0 has no effect. Reads return the corresponding enable bit's current value.
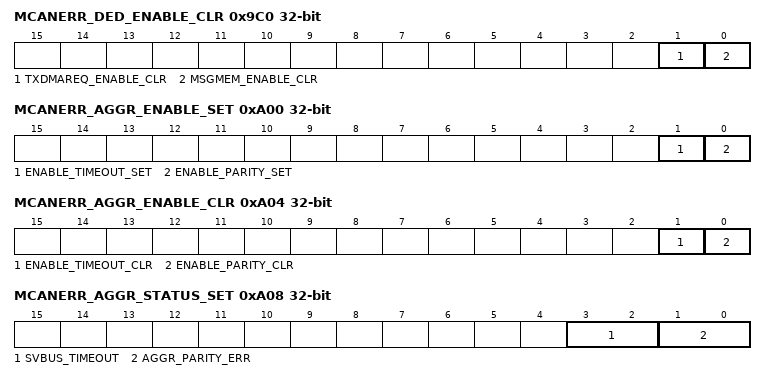
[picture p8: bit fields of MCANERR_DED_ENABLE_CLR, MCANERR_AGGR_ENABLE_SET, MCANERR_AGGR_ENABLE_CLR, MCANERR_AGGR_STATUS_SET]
0x9C0 MCANERR_DED_ENABLE_CLR — MCAN Double Error Detected Interrupt Enable Clear Register
  [1] TXDMAREQ_ENABLE_CLR rw — TX Empty DMA Request Parity Interrupt Pending Enable Clear. Writing a 1 to this bit disables the TX empty DMA request parity error interrupts. Writing a 0 has no effect. Reads return the corresponding enable bit's current value.
  [0] MSGMEM_ENABLE_CLR rw — Message RAM DED Interrupt Pending Enable Clear. Writing a 1 to this bit disables the Message RAM DED error interrupts. Writing a 0 has no effect. Reads return the corresponding enable bit's current value.
0xA00 MCANERR_AGGR_ENABLE_SET — MCAN Error Aggregator Enable Set Register
  [1] ENABLE_TIMEOUT_SET rw — Write 1 to enable timeout errors. Reads return the corresponding enable bit's current value.
  [0] ENABLE_PARITY_SET rw — Write 1 to enable parity errors. Reads return the corresponding enable bit's current value.
0xA04 MCANERR_AGGR_ENABLE_CLR — MCAN Error Aggregator Enable Clear Register
  [1] ENABLE_TIMEOUT_CLR rw — Write 1 to disable timeout errors. Reads return the corresponding enable bit's current value.
  [0] ENABLE_PARITY_CLR rw — Write 1 to disable parity errors. Reads return the corresponding enable bit's current value.
0xA08 MCANERR_AGGR_STATUS_SET — MCAN Error Aggregator Status Set Register
  [3:2] SVBUS_TIMEOUT rw — Aggregator Serial VBUS Timeout Error Status #br# #br#2-bit saturating counter of the number of SVBUS timeout errors that have occurred since last cleared. #br# 0 No timeout errors have occurred #br# 1 One timeout error has occurred #br# 2 Two timeout errors have occurred #br# 3 Three timeout errors have occurred #br# #br#A write of a non-zero value to this bit field increments it by the value provided.
  [1:0] AGGR_PARITY_ERR rw — Aggregator Parity Error Status #br# #br#2-bit saturating counter of the number of parity errors that have occurred since last cleared. #br# 0 No parity errors have occurred #br# 1 One parity error has occurred #br# 2 Two parity errors have occurred #br# 3 Three parity errors have occurred #br# #br#A write of a non-zero value to this bit field increments it by the value provided.
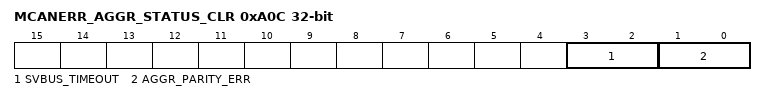
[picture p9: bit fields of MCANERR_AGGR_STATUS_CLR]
0xA0C MCANERR_AGGR_STATUS_CLR — MCAN Error Aggregator Status Clear Register
  [3:2] SVBUS_TIMEOUT rw — Aggregator Serial VBUS Timeout Error Status #br# #br#2-bit saturating counter of the number of SVBUS timeout errors that have occurred since last cleared. #br# 0 No timeout errors have occurred #br# 1 One timeout error has occurred #br# 2 Two timeout errors have occurred #br# 3 Three timeout errors have occurred #br# #br#A write of a non-zero value to this bit field decrements it by the value provided.
  [1:0] AGGR_PARITY_ERR rw — Aggregator Parity Error Status #br# #br#2-bit saturating counter of the number of parity errors that have occurred since last cleared. #br# 0 No parity errors have occurred #br# 1 One parity error has occurred #br# 2 Two parity errors have occurred #br# 3 Three parity errors have occurred #br# #br#A write of a non-zero value to this bit field decrements it by the value provided.
